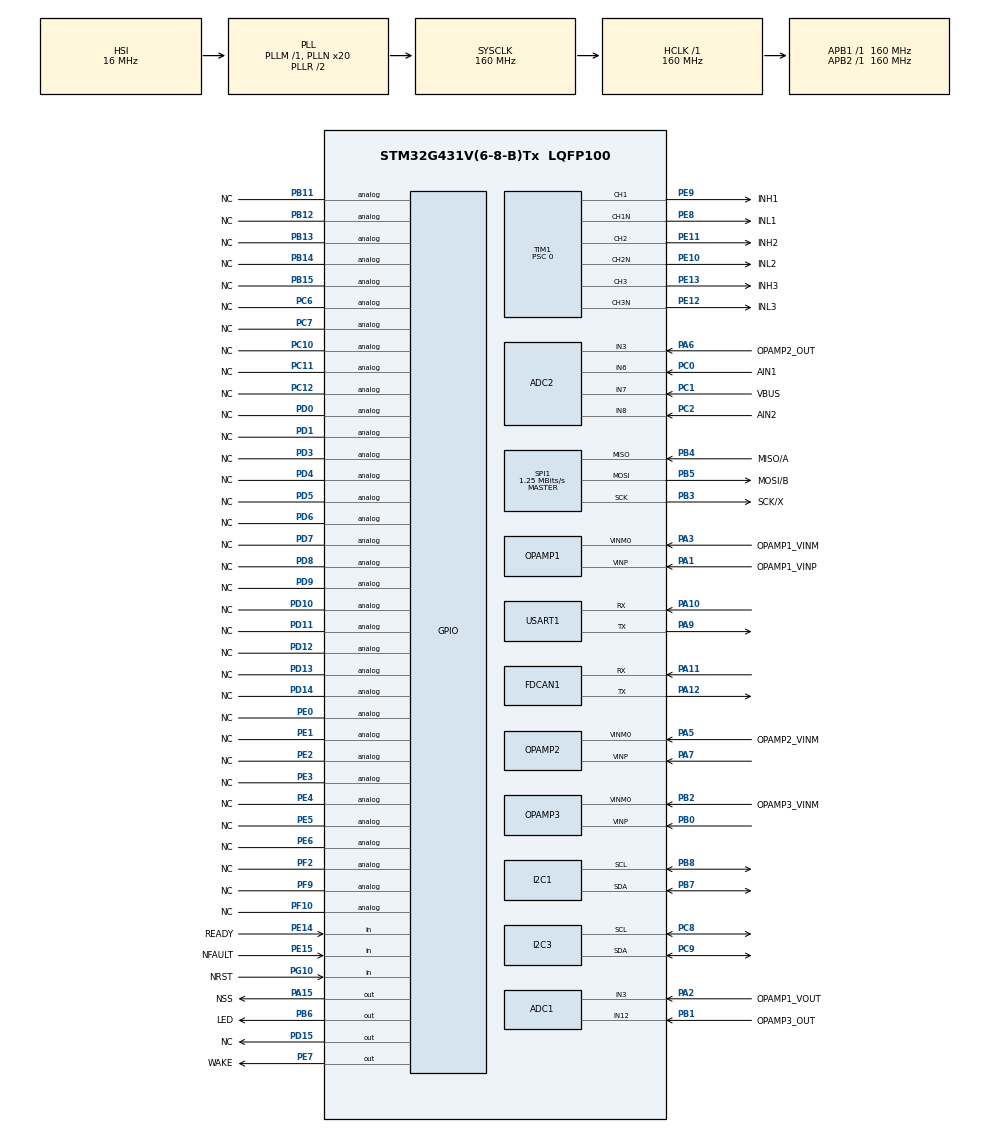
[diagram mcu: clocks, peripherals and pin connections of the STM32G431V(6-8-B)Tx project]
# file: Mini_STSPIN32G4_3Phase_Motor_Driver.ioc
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ADC1.Channel-0\#ChannelRegularConversion=ADC_CHANNEL_3
ADC1.Channel-5\#ChannelRegularConversion=ADC_CHANNEL_12
ADC1.Channel-6\#ChannelRegularConversion=ADC_CHANNEL_TEMPSENSOR_ADC1
ADC1.Channel-7\#ChannelRegularConversion=ADC_CHANNEL_VREFINT
ADC1.ContinuousConvMode=DISABLE
ADC1.DMAContinuousRequests=ENABLE
ADC1.EOCSelection=ADC_EOC_SEQ_CONV
ADC1.EnableInjectedConversion=DISABLE
ADC1.ExternalTrigConv=ADC_EXTERNALTRIG_T1_TRGO
ADC1.Mode=ADC_MODE_INDEPENDENT
ADC1.NbrOfConversion=4
ADC1.NbrOfConversionFlag=1
ADC1.OffsetNumber-0\#ChannelRegularConversion=ADC_OFFSET_NONE
ADC1.OffsetNumber-5\#ChannelRegularConversion=ADC_OFFSET_NONE
ADC1.OffsetNumber-6\#ChannelRegularConversion=ADC_OFFSET_NONE
ADC1.OffsetNumber-7\#ChannelRegularConversion=ADC_OFFSET_NONE
ADC1.Overrun=ADC_OVR_DATA_OVERWRITTEN
ADC1.OversamplingMode=DISABLE
ADC1.Rank-0\#ChannelRegularConversion=1
ADC1.Rank-5\#ChannelRegularConversion=2
ADC1.Rank-6\#ChannelRegularConversion=3
ADC1.Rank-7\#ChannelRegularConversion=4
ADC1.Rank1_Channel=ADC_CHANNEL_3
ADC1.Rank2_Channel=ADC_CHANNEL_3
ADC1.Rank3_Channel=ADC_CHANNEL_3
ADC1.Rank4_Channel=ADC_CHANNEL_3
ADC1.SamplingTime-0\#ChannelRegularConversion=ADC_SAMPLETIME_6CYCLES_5
ADC1.SamplingTime-5\#ChannelRegularConversion=ADC_SAMPLETIME_6CYCLES_5
ADC1.SamplingTime-6\#ChannelRegularConversion=ADC_SAMPLETIME_247CYCLES_5
ADC1.SamplingTime-7\#ChannelRegularConversion=ADC_SAMPLETIME_247CYCLES_5
ADC1.master=1
ADC2.Channel-5\#ChannelRegularConversion=ADC_CHANNEL_3
ADC2.Channel-6\#ChannelRegularConversion=ADC_CHANNEL_8
ADC2.Channel-7\#ChannelRegularConversion=ADC_CHANNEL_6
ADC2.Channel-8\#ChannelRegularConversion=ADC_CHANNEL_7
ADC2.ContinuousConvMode=DISABLE
ADC2.DMAContinuousRequests=ENABLE
ADC2.EOCSelection=ADC_EOC_SEQ_CONV
ADC2.EnableInjectedConversion=DISABLE
ADC2.EnableRegularConversion=ENABLE
ADC2.ExternalTrigConv=ADC_EXTERNALTRIG_T1_TRGO
ADC2.NbrOfConversion=4
ADC2.NbrOfConversionFlag=1
ADC2.OffsetNumber-5\#ChannelRegularConversion=ADC_OFFSET_NONE
ADC2.OffsetNumber-6\#ChannelRegularConversion=ADC_OFFSET_NONE
ADC2.OffsetNumber-7\#ChannelRegularConversion=ADC_OFFSET_NONE
ADC2.OffsetNumber-8\#ChannelRegularConversion=ADC_OFFSET_NONE
ADC2.Overrun=ADC_OVR_DATA_OVERWRITTEN
ADC2.OversamplingMode=DISABLE
ADC2.Rank-5\#ChannelRegularConversion=1
ADC2.Rank-6\#ChannelRegularConversion=2
ADC2.Rank-7\#ChannelRegularConversion=3
ADC2.Rank-8\#ChannelRegularConversion=4
ADC2.Rank1_Channel=ADC_CHANNEL_3
ADC2.Rank2_Channel=ADC_CHANNEL_6
ADC2.Rank3_Channel=ADC_CHANNEL_7
ADC2.Rank4_Channel=ADC_CHANNEL_8
ADC2.SamplingTime-5\#ChannelRegularConversion=ADC_SAMPLETIME_6CYCLES_5
ADC2.SamplingTime-6\#ChannelRegularConversion=ADC_SAMPLETIME_6CYCLES_5
ADC2.SamplingTime-7\#ChannelRegularConversion=ADC_SAMPLETIME_6CYCLES_5
ADC2.SamplingTime-8\#ChannelRegularConversion=ADC_SAMPLETIME_6CYCLES_5
Dma.ADC1.1.Direction=DMA_PERIPH_TO_MEMORY
Dma.ADC1.1.EventEnable=DISABLE
Dma.ADC1.1.Instance=DMA1_Channel2
Dma.ADC1.1.MemDataAlignment=DMA_MDATAALIGN_HALFWORD
Dma.ADC1.1.MemInc=DMA_MINC_ENABLE
Dma.ADC1.1.Mode=DMA_CIRCULAR
Dma.ADC1.1.PeriphDataAlignment=DMA_PDATAALIGN_HALFWORD
Dma.ADC1.1.PeriphInc=DMA_PINC_DISABLE
Dma.ADC1.1.Polarity=HAL_DMAMUX_REQ_GEN_RISING
Dma.ADC1.1.Priority=DMA_PRIORITY_HIGH
Dma.ADC1.1.RequestNumber=1
Dma.ADC1.1.SignalID=NONE
Dma.ADC1.1.SyncEnable=DISABLE
Dma.ADC1.1.SyncPolarity=HAL_DMAMUX_SYNC_NO_EVENT
Dma.ADC1.1.SyncRequestNumber=1
Dma.ADC1.1.SyncSignalID=NONE
Dma.ADC2.0.Direction=DMA_PERIPH_TO_MEMORY
Dma.ADC2.0.EventEnable=DISABLE
Dma.ADC2.0.Instance=DMA1_Channel3
Dma.ADC2.0.MemDataAlignment=DMA_MDATAALIGN_HALFWORD
Dma.ADC2.0.MemInc=DMA_MINC_ENABLE
Dma.ADC2.0.Mode=DMA_CIRCULAR
Dma.ADC2.0.PeriphDataAlignment=DMA_PDATAALIGN_HALFWORD
Dma.ADC2.0.PeriphInc=DMA_PINC_DISABLE
Dma.ADC2.0.Polarity=HAL_DMAMUX_REQ_GEN_RISING
Dma.ADC2.0.Priority=DMA_PRIORITY_HIGH
Dma.ADC2.0.RequestNumber=1
Dma.ADC2.0.SignalID=NONE
Dma.ADC2.0.SyncEnable=DISABLE
Dma.ADC2.0.SyncPolarity=HAL_DMAMUX_SYNC_NO_EVENT
Dma.ADC2.0.SyncRequestNumber=1
Dma.ADC2.0.SyncSignalID=NONE
Dma.MEMTOMEM.3.Direction=DMA_MEMORY_TO_MEMORY
Dma.MEMTOMEM.3.EventEnable=DISABLE
Dma.MEMTOMEM.3.Instance=DMA1_Channel4
Dma.MEMTOMEM.3.MemDataAlignment=DMA_MDATAALIGN_HALFWORD
Dma.MEMTOMEM.3.MemInc=DMA_MINC_ENABLE
Dma.MEMTOMEM.3.Mode=DMA_NORMAL
Dma.MEMTOMEM.3.PeriphDataAlignment=DMA_PDATAALIGN_HALFWORD
Dma.MEMTOMEM.3.PeriphInc=DMA_PINC_ENABLE
Dma.MEMTOMEM.3.Polarity=HAL_DMAMUX_REQ_GEN_RISING
Dma.MEMTOMEM.3.Priority=DMA_PRIORITY_LOW
Dma.MEMTOMEM.3.RequestNumber=1
Dma.MEMTOMEM.3.SignalID=NONE
Dma.MEMTOMEM.3.SyncEnable=DISABLE
Dma.MEMTOMEM.3.SyncPolarity=HAL_DMAMUX_SYNC_NO_EVENT
Dma.MEMTOMEM.3.SyncRequestNumber=1
Dma.MEMTOMEM.3.SyncSignalID=NONE
Dma.MEMTOMEM.4.Direction=DMA_MEMORY_TO_MEMORY
Dma.MEMTOMEM.4.EventEnable=DISABLE
Dma.MEMTOMEM.4.Instance=DMA1_Channel5
Dma.MEMTOMEM.4.MemDataAlignment=DMA_MDATAALIGN_HALFWORD
Dma.MEMTOMEM.4.MemInc=DMA_MINC_ENABLE
Dma.MEMTOMEM.4.Mode=DMA_NORMAL
Dma.MEMTOMEM.4.PeriphDataAlignment=DMA_PDATAALIGN_HALFWORD
Dma.MEMTOMEM.4.PeriphInc=DMA_PINC_ENABLE
Dma.MEMTOMEM.4.Polarity=HAL_DMAMUX_REQ_GEN_RISING
Dma.MEMTOMEM.4.Priority=DMA_PRIORITY_LOW
Dma.MEMTOMEM.4.RequestNumber=1
Dma.MEMTOMEM.4.SignalID=NONE
Dma.MEMTOMEM.4.SyncEnable=DISABLE
Dma.MEMTOMEM.4.SyncPolarity=HAL_DMAMUX_SYNC_NO_EVENT
Dma.MEMTOMEM.4.SyncRequestNumber=1
Dma.MEMTOMEM.4.SyncSignalID=NONE
Dma.Request0=ADC2
Dma.Request1=ADC1
Dma.Request2=USART1_TX
Dma.Request3=MEMTOMEM
Dma.Request4=MEMTOMEM
Dma.Request5=SPI1_RX
Dma.Request6=SPI1_TX
Dma.SPI1_RX.5.Direction=DMA_PERIPH_TO_MEMORY
Dma.SPI1_RX.5.EventEnable=DISABLE
Dma.SPI1_RX.5.Instance=DMA2_Channel1
Dma.SPI1_RX.5.MemDataAlignment=DMA_MDATAALIGN_HALFWORD
Dma.SPI1_RX.5.MemInc=DMA_MINC_ENABLE
Dma.SPI1_RX.5.Mode=DMA_NORMAL
Dma.SPI1_RX.5.PeriphDataAlignment=DMA_PDATAALIGN_HALFWORD
Dma.SPI1_RX.5.PeriphInc=DMA_PINC_DISABLE
Dma.SPI1_RX.5.Polarity=HAL_DMAMUX_REQ_GEN_RISING
Dma.SPI1_RX.5.Priority=DMA_PRIORITY_VERY_HIGH
Dma.SPI1_RX.5.RequestNumber=1
Dma.SPI1_RX.5.SignalID=NONE
Dma.SPI1_RX.5.SyncEnable=DISABLE
Dma.SPI1_RX.5.SyncPolarity=HAL_DMAMUX_SYNC_NO_EVENT
Dma.SPI1_RX.5.SyncRequestNumber=1
Dma.SPI1_RX.5.SyncSignalID=NONE
Dma.SPI1_TX.6.Direction=DMA_MEMORY_TO_PERIPH
Dma.SPI1_TX.6.EventEnable=DISABLE
Dma.SPI1_TX.6.Instance=DMA2_Channel2
Dma.SPI1_TX.6.MemDataAlignment=DMA_MDATAALIGN_HALFWORD
Dma.SPI1_TX.6.MemInc=DMA_MINC_ENABLE
Dma.SPI1_TX.6.Mode=DMA_NORMAL
Dma.SPI1_TX.6.PeriphDataAlignment=DMA_PDATAALIGN_HALFWORD
Dma.SPI1_TX.6.PeriphInc=DMA_PINC_DISABLE
Dma.SPI1_TX.6.Polarity=HAL_DMAMUX_REQ_GEN_RISING
Dma.SPI1_TX.6.Priority=DMA_PRIORITY_VERY_HIGH
Dma.SPI1_TX.6.RequestNumber=1
Dma.SPI1_TX.6.SignalID=NONE
Dma.SPI1_TX.6.SyncEnable=DISABLE
Dma.SPI1_TX.6.SyncPolarity=HAL_DMAMUX_SYNC_NO_EVENT
Dma.SPI1_TX.6.SyncRequestNumber=1
Dma.SPI1_TX.6.SyncSignalID=NONE
Dma.USART1_TX.2.Direction=DMA_MEMORY_TO_PERIPH
Dma.USART1_TX.2.EventEnable=DISABLE
Dma.USART1_TX.2.Instance=DMA1_Channel1
Dma.USART1_TX.2.MemDataAlignment=DMA_MDATAALIGN_BYTE
Dma.USART1_TX.2.MemInc=DMA_MINC_ENABLE
Dma.USART1_TX.2.Mode=DMA_NORMAL
Dma.USART1_TX.2.PeriphDataAlignment=DMA_PDATAALIGN_BYTE
Dma.USART1_TX.2.PeriphInc=DMA_PINC_DISABLE
Dma.USART1_TX.2.Polarity=HAL_DMAMUX_REQ_GEN_RISING
Dma.USART1_TX.2.Priority=DMA_PRIORITY_LOW
Dma.USART1_TX.2.RequestNumber=1
Dma.USART1_TX.2.SignalID=NONE
Dma.USART1_TX.2.SyncEnable=DISABLE
Dma.USART1_TX.2.SyncPolarity=HAL_DMAMUX_SYNC_NO_EVENT
Dma.USART1_TX.2.SyncRequestNumber=1
Dma.USART1_TX.2.SyncSignalID=NONE
FDCAN1.CalculateBaudRateNominal=3333333
FDCAN1.CalculateTimeBitNominal=300
FDCAN1.CalculateTimeQuantumNominal=100.0
I2C1.Timing=0x30D29DE4
I2C3.Timing=0x30D29DE4
Mcu.Family=STM32G4
Mcu.Name=STM32G431V(6-8-B)Tx
Mcu.Package=LQFP100
Mcu.UserConstants=TIM1_COUNT_MAX,8000
NVIC.ADC1_2_IRQn=true\:0\:0\:true\:false\:true\:true\:true\:true
NVIC.DMA1_Channel1_IRQn=true\:1\:0\:true\:false\:true\:false\:true\:true
NVIC.DMA1_Channel2_IRQn=true\:1\:0\:true\:false\:true\:false\:true\:true
NVIC.DMA1_Channel3_IRQn=true\:1\:0\:true\:false\:true\:false\:true\:true
NVIC.DMA2_Channel1_IRQn=true\:0\:0\:false\:false\:true\:false\:true\:true
NVIC.DMA2_Channel2_IRQn=true\:0\:0\:false\:false\:true\:false\:true\:true
NVIC.PriorityGroup=NVIC_PRIORITYGROUP_4
NVIC.SPI1_IRQn=true\:0\:0\:false\:false\:true\:true\:true\:true
NVIC.TIM1_UP_TIM16_IRQn=true\:2\:0\:true\:false\:true\:true\:true\:true
NVIC.USART1_IRQn=true\:0\:0\:true\:false\:true\:true\:true\:true
OPAMP1.PgaGain=OPAMP_PGA_GAIN_16_OR_MINUS_15
OPAMP1.PowerMode=OPAMP_POWERMODE_HIGHSPEED
OPAMP2.PgaGain=OPAMP_PGA_GAIN_16_OR_MINUS_15
OPAMP2.PowerMode=OPAMP_POWERMODE_HIGHSPEED
OPAMP3.PgaGain=OPAMP_PGA_GAIN_16_OR_MINUS_15
OPAMP3.PowerMode=OPAMP_POWERMODE_HIGHSPEED
PA1.GPIO_Label=OPAMP1_VINP
PA1.Mode=PGA Connected-INVERTINGINPUT_IO0_BIAS
PA1.Signal=OPAMP1_VINP
PA10.Mode=Asynchronous
PA10.Signal=USART1_RX
PA11.Mode=FDCAN_Activate
PA11.Signal=FDCAN1_RX
PA12.Mode=FDCAN_Activate
PA12.Signal=FDCAN1_TX
PA13.GPIO_Label=SWDIO
PA13.Mode=Serial_Wire
PA13.Signal=SYS_JTMS-SWDIO
PA14.GPIO_Label=SWCLK
PA14.Mode=Serial_Wire
PA14.Signal=SYS_JTCK-SWCLK
PA15.GPIO_Label=NSS
PA15.Signal=GPIO_Output
PA2.GPIO_Label=OPAMP1_VOUT
PA2.Signal=SharedAnalog_PA2
PA3.GPIO_Label=OPAMP1_VINM
PA3.Mode=PGA Connected-INVERTINGINPUT_IO0_BIAS
PA3.Signal=OPAMP1_VINM0
PA5.GPIO_Label=OPAMP2_VINM
PA5.Mode=PGA Connected-INVERTINGINPUT_IO0_BIAS
PA5.Signal=OPAMP2_VINM0
PA6.GPIO_Label=OPAMP2_OUT
PA6.Signal=SharedAnalog_PA6
PA7.Mode=PGA Connected-INVERTINGINPUT_IO0_BIAS
PA7.Signal=OPAMP2_VINP
PA9.Mode=Asynchronous
PA9.Signal=USART1_TX
PB0.Mode=PGA Connected-INVERTINGINPUT_IO0_BIAS
PB0.Signal=OPAMP3_VINP
PB1.GPIO_Label=OPAMP3_OUT
PB1.Signal=SharedAnalog_PB1
PB11.GPIO_Label=NC
PB11.Signal=GPIO_Analog
PB12.GPIO_Label=NC
PB12.Signal=GPIO_Analog
PB13.GPIO_Label=NC
PB13.Signal=GPIO_Analog
PB14.GPIO_Label=NC
PB14.Signal=GPIO_Analog
PB15.GPIO_Label=NC
PB15.Signal=GPIO_Analog
PB2.GPIO_Label=OPAMP3_VINM
PB2.Mode=PGA Connected-INVERTINGINPUT_IO0_BIAS
PB2.Signal=OPAMP3_VINM0
PB3.GPIO_Label=SCK/X
PB3.Mode=Full_Duplex_Master
PB3.Signal=SPI1_SCK
PB4.GPIO_Label=MISO/A
PB4.Mode=Full_Duplex_Master
PB4.Signal=SPI1_MISO
PB5.GPIO_Label=MOSI/B
PB5.Mode=Full_Duplex_Master
PB5.Signal=SPI1_MOSI
PB6.GPIO_Label=LED
PB6.Signal=GPIO_Output
PB7.Mode=I2C
PB7.Signal=I2C1_SDA
PB8-BOOT0.Mode=I2C
PB8-BOOT0.Signal=I2C1_SCL
PC0.GPIO_Label=AIN1
PC0.Mode=IN6-Single-Ended
PC0.Signal=ADC2_IN6
PC1.GPIO_Label=VBUS
PC1.Mode=IN7-Single-Ended
PC1.Signal=ADC2_IN7
PC10.GPIO_Label=NC
PC10.Signal=GPIO_Analog
PC11.GPIO_Label=NC
PC11.Signal=GPIO_Analog
PC12.GPIO_Label=NC
PC12.Signal=GPIO_Analog
PC2.GPIO_Label=AIN2
PC2.Mode=IN8-Single-Ended
PC2.Signal=ADC2_IN8
PC6.GPIO_Label=NC
PC6.Signal=GPIO_Analog
PC7.GPIO_Label=NC
PC7.Signal=GPIO_Analog
PC8.Mode=I2C
PC8.Signal=I2C3_SCL
PC9.Mode=I2C
PC9.Signal=I2C3_SDA
PD0.GPIO_Label=NC
PD0.Signal=GPIO_Analog
PD1.GPIO_Label=NC
PD1.Signal=GPIO_Analog
PD10.GPIO_Label=NC
PD10.Signal=GPIO_Analog
PD11.GPIO_Label=NC
PD11.Signal=GPIO_Analog
PD12.GPIO_Label=NC
PD12.Signal=GPIO_Analog
PD13.GPIO_Label=NC
PD13.Signal=GPIO_Analog
PD14.GPIO_Label=NC
PD14.Signal=GPIO_Analog
PD15.GPIO_Label=NC
PD15.Signal=GPIO_Output
PD3.GPIO_Label=NC
PD3.Signal=GPIO_Analog
PD4.GPIO_Label=NC
PD4.Signal=GPIO_Analog
PD5.GPIO_Label=NC
PD5.Signal=GPIO_Analog
PD6.GPIO_Label=NC
PD6.Signal=GPIO_Analog
PD7.GPIO_Label=NC
PD7.Signal=GPIO_Analog
PD8.GPIO_Label=NC
PD8.Signal=GPIO_Analog
PD9.GPIO_Label=NC
PD9.Signal=GPIO_Analog
PE0.GPIO_Label=NC
PE0.Signal=GPIO_Analog
PE1.GPIO_Label=NC
PE1.Signal=GPIO_Analog
PE10.GPIO_Label=INL2
PE10.Mode=PWM Generation2 CH2 CH2N
PE10.Signal=TIM1_CH2N
PE11.GPIO_Label=INH2
PE11.Signal=S_TIM1_CH2
PE12.GPIO_Label=INL3
PE12.Mode=PWM Generation3 CH3 CH3N
PE12.Signal=TIM1_CH3N
PE13.GPIO_Label=INH3
PE13.Signal=S_TIM1_CH3
PE14.GPIO_Label=READY
PE14.Signal=GPIO_Input
PE15.GPIO_Label=NFAULT
PE15.Signal=GPIO_Input
PE2.GPIO_Label=NC
PE2.Signal=GPIO_Analog
PE3.GPIO_Label=NC
PE3.Signal=GPIO_Analog
PE4.GPIO_Label=NC
PE4.Signal=GPIO_Analog
PE5.GPIO_Label=NC
PE5.Signal=GPIO_Analog
PE6.GPIO_Label=NC
PE6.Signal=GPIO_Analog
PE7.GPIO_Label=WAKE
PE7.Signal=GPIO_Output
PE8.GPIO_Label=INL1
PE8.Mode=PWM Generation1 CH1 CH1N
PE8.Signal=TIM1_CH1N
PE9.GPIO_Label=INH1
PE9.Signal=S_TIM1_CH1
PF0-OSC_IN.Mode=HSE-External-Oscillator
PF0-OSC_IN.Signal=RCC_OSC_IN
PF1-OSC_OUT.Mode=HSE-External-Oscillator
PF1-OSC_OUT.Signal=RCC_OSC_OUT
PF10.GPIO_Label=NC
PF10.Signal=GPIO_Analog
PF2.GPIO_Label=NC
PF2.Signal=GPIO_Analog
PF9.GPIO_Label=NC
PF9.Signal=GPIO_Analog
PG10-NRST.GPIO_Label=NRST
PG10-NRST.Signal=GPIO_Input
ProjectManager.HeapSize=0x200
ProjectManager.StackSize=0x400
ProjectManager.TargetToolchain=CMake
RCC.ADC12Freq_Value=160000000
RCC.AHBFreq_Value=160000000
RCC.APB1Freq_Value=160000000
RCC.APB1TimFreq_Value=160000000
RCC.APB2Freq_Value=160000000
RCC.APB2TimFreq_Value=160000000
RCC.CortexFreq_Value=160000000
RCC.EXTERNAL_CLOCK_VALUE=12288000
RCC.HCLKFreq_Value=160000000
RCC.HSE_VALUE=16000000
RCC.HSI48_VALUE=48000000
RCC.HSI_VALUE=16000000
RCC.LSE_VALUE=32768
RCC.PLLN=20
RCC.SYSCLKFreq_VALUE=160000000
RCC.SYSCLKSource=RCC_SYSCLKSOURCE_PLLCLK
RCC.USBFreq_Value=160000000
RCC.VCOOutputFreq_Value=320000000
SH.S_TIM1_CH1.0=TIM1_CH1,PWM Generation1 CH1 CH1N
SH.S_TIM1_CH2.0=TIM1_CH2,PWM Generation2 CH2 CH2N
SH.S_TIM1_CH3.0=TIM1_CH3,PWM Generation3 CH3 CH3N
SH.SharedAnalog_PA2.0=ADC1_IN3,IN3-Single-Ended
SH.SharedAnalog_PA2.1=OPAMP1_VOUT,PGA Connected-INVERTINGINPUT_IO0_BIAS
SH.SharedAnalog_PA6.0=ADC2_IN3,IN3-Single-Ended
SH.SharedAnalog_PA6.1=OPAMP2_VOUT,PGA Connected-INVERTINGINPUT_IO0_BIAS
SH.SharedAnalog_PB1.0=ADC1_IN12,IN12-Single-Ended
SH.SharedAnalog_PB1.1=OPAMP3_VOUT,PGA Connected-INVERTINGINPUT_IO0_BIAS
SPI1.BaudRatePrescaler=SPI_BAUDRATEPRESCALER_128
SPI1.CLKPhase=SPI_PHASE_2EDGE
SPI1.CalculateBaudRate=1.25 MBits/s
SPI1.DataSize=SPI_DATASIZE_16BIT
SPI1.Direction=SPI_DIRECTION_2LINES
SPI1.Mode=SPI_MODE_MASTER
SPI1.VirtualType=VM_MASTER
TIM1.AutoReloadPreload=TIM_AUTORELOAD_PRELOAD_ENABLE
TIM1.Channel-PWM\ Generation1\ CH1\ CH1N=TIM_CHANNEL_1
TIM1.Channel-PWM\ Generation2\ CH2\ CH2N=TIM_CHANNEL_2
TIM1.Channel-PWM\ Generation3\ CH3\ CH3N=TIM_CHANNEL_3
TIM1.CounterMode=TIM_COUNTERMODE_CENTERALIGNED2
TIM1.OC1Preload_PWM=ENABLE
TIM1.OCMode_PWM-PWM\ Generation1\ CH1\ CH1N=TIM_OCMODE_PWM2
TIM1.OCMode_PWM-PWM\ Generation2\ CH2\ CH2N=TIM_OCMODE_PWM2
TIM1.OCMode_PWM-PWM\ Generation3\ CH3\ CH3N=TIM_OCMODE_PWM2
TIM1.PeriodNoDither=TIM1_COUNT_MAX
TIM1.Prescaler=0
TIM1.PulseNoDither_1=TIM1_COUNT_MAX
TIM1.PulseNoDither_2=TIM1_COUNT_MAX
TIM1.PulseNoDither_3=TIM1_COUNT_MAX
TIM1.RepetitionCounter=1
TIM1.TIM_MasterOutputTrigger=TIM_TRGO_UPDATE
TIM1.TIM_MasterOutputTrigger2=TIM_TRGO2_RESET
TIM1.TIM_MasterSlaveMode=TIM_MASTERSLAVEMODE_DISABLE
USART1.VirtualMode-Asynchronous=VM_ASYNC
VP_ADC1_TempSens_Input.Mode=IN-TempSens
VP_ADC1_Vref_Input.Mode=IN-Vrefint
VP_SYS_VS_DBSignals.Mode=DisableDeadBatterySignals
VP_TIM1_VS_ClockSourceINT.Mode=Internal
VP_TIM4_VS_ClockSourceINT.Mode=Internal
board=custom

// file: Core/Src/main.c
/* USER CODE BEGIN Header */
/**
  ******************************************************************************
  * @file           : main.c
  * @brief          : Main program body
  ******************************************************************************
  * @attention
  *
  * Copyright (c) 2026 STMicroelectronics.
  * All rights reserved.
  *
  * This software is licensed under terms that can be found in the LICENSE file
  * in the root directory of this software component.
  * If no LICENSE file comes with this software, it is provided AS-IS.
  *
  ******************************************************************************
  */
/* USER CODE END Header */
#include "main.h"

/* USER CODE BEGIN Includes */
#include "main_task.h"
/* USER CODE END Includes */

ADC_HandleTypeDef hadc1;
ADC_HandleTypeDef hadc2;
DMA_HandleTypeDef hdma_adc1;
DMA_HandleTypeDef hdma_adc2;

FDCAN_HandleTypeDef hfdcan1;

I2C_HandleTypeDef hi2c1;
I2C_HandleTypeDef hi2c3;

OPAMP_HandleTypeDef hopamp1;
OPAMP_HandleTypeDef hopamp2;
OPAMP_HandleTypeDef hopamp3;

SPI_HandleTypeDef hspi1;
DMA_HandleTypeDef hdma_spi1_rx;
DMA_HandleTypeDef hdma_spi1_tx;

TIM_HandleTypeDef htim1;
TIM_HandleTypeDef htim4;

UART_HandleTypeDef huart1;
DMA_HandleTypeDef hdma_usart1_tx;

DMA_HandleTypeDef hdma_memtomem_dma1_channel4;
DMA_HandleTypeDef hdma_memtomem_dma1_channel5;

void SystemClock_Config(void);
static void MX_GPIO_Init(void);
static void MX_DMA_Init(void);
static void MX_ADC1_Init(void);
static void MX_ADC2_Init(void);
static void MX_FDCAN1_Init(void);
static void MX_OPAMP1_Init(void);
static void MX_OPAMP2_Init(void);
static void MX_OPAMP3_Init(void);
static void MX_TIM1_Init(void);
static void MX_I2C1_Init(void);
static void MX_I2C3_Init(void);
static void MX_USART1_UART_Init(void);
static void MX_SPI1_Init(void);
static void MX_TIM4_Init(void);

int main(void)
{

  /* MCU Configuration--------------------------------------------------------*/

  /* Reset of all peripherals, Initializes the Flash interface and the Systick. */
  HAL_Init();

  /* Configure the system clock */
  SystemClock_Config();

  /* Initialize all configured peripherals */
  MX_GPIO_Init();
  MX_DMA_Init();
  MX_ADC1_Init();
  MX_ADC2_Init();
  MX_FDCAN1_Init();
  MX_OPAMP1_Init();
  MX_OPAMP2_Init();
  MX_OPAMP3_Init();
  MX_TIM1_Init();
  MX_I2C1_Init();
  MX_I2C3_Init();
  MX_USART1_UART_Init();
  MX_SPI1_Init();
  MX_TIM4_Init();

  /* Infinite loop */
  /* USER CODE BEGIN WHILE */
  while (1)
  {
    main_task();
    /* USER CODE END WHILE */

  }
}

void SystemClock_Config(void)
{
  RCC_OscInitTypeDef RCC_OscInitStruct = {0};
  RCC_ClkInitTypeDef RCC_ClkInitStruct = {0};

  /** Configure the main internal regulator output voltage
  */
  HAL_PWREx_ControlVoltageScaling(PWR_REGULATOR_VOLTAGE_SCALE1_BOOST);

  /** Initializes the RCC Oscillators according to the specified parameters
  * in the RCC_OscInitTypeDef structure.
  */
  RCC_OscInitStruct.OscillatorType = RCC_OSCILLATORTYPE_HSI;
  RCC_OscInitStruct.HSIState = RCC_HSI_ON;
  RCC_OscInitStruct.HSICalibrationValue = RCC_HSICALIBRATION_DEFAULT;
  RCC_OscInitStruct.PLL.PLLState = RCC_PLL_ON;
  RCC_OscInitStruct.PLL.PLLSource = RCC_PLLSOURCE_HSI;
  RCC_OscInitStruct.PLL.PLLM = RCC_PLLM_DIV1;
  RCC_OscInitStruct.PLL.PLLN = 20;
  RCC_OscInitStruct.PLL.PLLP = RCC_PLLP_DIV2;
  RCC_OscInitStruct.PLL.PLLQ = RCC_PLLQ_DIV2;
  RCC_OscInitStruct.PLL.PLLR = RCC_PLLR_DIV2;
  if (HAL_RCC_OscConfig(&RCC_OscInitStruct) != HAL_OK)
  {
    Error_Handler();
  }

  /** Initializes the CPU, AHB and APB buses clocks
  */
  RCC_ClkInitStruct.ClockType = RCC_CLOCKTYPE_HCLK|RCC_CLOCKTYPE_SYSCLK
                              |RCC_CLOCKTYPE_PCLK1|RCC_CLOCKTYPE_PCLK2;
  RCC_ClkInitStruct.SYSCLKSource = RCC_SYSCLKSOURCE_PLLCLK;
  RCC_ClkInitStruct.AHBCLKDivider = RCC_SYSCLK_DIV1;
  RCC_ClkInitStruct.APB1CLKDivider = RCC_HCLK_DIV1;
  RCC_ClkInitStruct.APB2CLKDivider = RCC_HCLK_DIV1;

  if (HAL_RCC_ClockConfig(&RCC_ClkInitStruct, FLASH_LATENCY_4) != HAL_OK)
  {
    Error_Handler();
  }
}

static void MX_ADC1_Init(void)
{

  ADC_MultiModeTypeDef multimode = {0};
  ADC_ChannelConfTypeDef sConfig = {0};

  /** Common config
  */
  hadc1.Instance = ADC1;
  hadc1.Init.ClockPrescaler = ADC_CLOCK_SYNC_PCLK_DIV4;
  hadc1.Init.Resolution = ADC_RESOLUTION_12B;
  hadc1.Init.DataAlign = ADC_DATAALIGN_RIGHT;
  hadc1.Init.GainCompensation = 0;
  hadc1.Init.ScanConvMode = ADC_SCAN_ENABLE;
  hadc1.Init.EOCSelection = ADC_EOC_SEQ_CONV;
  hadc1.Init.LowPowerAutoWait = DISABLE;
  hadc1.Init.ContinuousConvMode = DISABLE;
  hadc1.Init.NbrOfConversion = 4;
  hadc1.Init.DiscontinuousConvMode = DISABLE;
  hadc1.Init.ExternalTrigConv = ADC_EXTERNALTRIG_T1_TRGO;
  hadc1.Init.ExternalTrigConvEdge = ADC_EXTERNALTRIGCONVEDGE_RISING;
  hadc1.Init.DMAContinuousRequests = ENABLE;
  hadc1.Init.Overrun = ADC_OVR_DATA_OVERWRITTEN;
  hadc1.Init.OversamplingMode = DISABLE;
  if (HAL_ADC_Init(&hadc1) != HAL_OK)
  {
    Error_Handler();
  }

  /** Configure the ADC multi-mode
  */
  multimode.Mode = ADC_MODE_INDEPENDENT;
  if (HAL_ADCEx_MultiModeConfigChannel(&hadc1, &multimode) != HAL_OK)
  {
    Error_Handler();
  }

  /** Configure Regular Channel
  */
  sConfig.Channel = ADC_CHANNEL_3;
  sConfig.Rank = ADC_REGULAR_RANK_1;
  sConfig.SamplingTime = ADC_SAMPLETIME_6CYCLES_5;
  sConfig.SingleDiff = ADC_SINGLE_ENDED;
  sConfig.OffsetNumber = ADC_OFFSET_NONE;
  sConfig.Offset = 0;
  if (HAL_ADC_ConfigChannel(&hadc1, &sConfig) != HAL_OK)
  {
    Error_Handler();
  }

  /** Configure Regular Channel
  */
  sConfig.Channel = ADC_CHANNEL_12;
  sConfig.Rank = ADC_REGULAR_RANK_2;
  if (HAL_ADC_ConfigChannel(&hadc1, &sConfig) != HAL_OK)
  {
    Error_Handler();
  }

  /** Configure Regular Channel
  */
  sConfig.Channel = ADC_CHANNEL_TEMPSENSOR_ADC1;
  sConfig.Rank = ADC_REGULAR_RANK_3;
  sConfig.SamplingTime = ADC_SAMPLETIME_247CYCLES_5;
  if (HAL_ADC_ConfigChannel(&hadc1, &sConfig) != HAL_OK)
  {
    Error_Handler();
  }

  /** Configure Regular Channel
  */
  sConfig.Channel = ADC_CHANNEL_VREFINT;
  sConfig.Rank = ADC_REGULAR_RANK_4;
  if (HAL_ADC_ConfigChannel(&hadc1, &sConfig) != HAL_OK)
  {
    Error_Handler();
  }

}

static void MX_ADC2_Init(void)
{

  ADC_ChannelConfTypeDef sConfig = {0};

  /** Common config
  */
  hadc2.Instance = ADC2;
  hadc2.Init.ClockPrescaler = ADC_CLOCK_SYNC_PCLK_DIV4;
  hadc2.Init.Resolution = ADC_RESOLUTION_12B;
  hadc2.Init.DataAlign = ADC_DATAALIGN_RIGHT;
  hadc2.Init.GainCompensation = 0;
  hadc2.Init.ScanConvMode = ADC_SCAN_ENABLE;
  hadc2.Init.EOCSelection = ADC_EOC_SEQ_CONV;
  hadc2.Init.LowPowerAutoWait = DISABLE;
  hadc2.Init.ContinuousConvMode = DISABLE;
  hadc2.Init.NbrOfConversion = 4;
  hadc2.Init.DiscontinuousConvMode = DISABLE;
  hadc2.Init.ExternalTrigConv = ADC_EXTERNALTRIG_T1_TRGO;
  hadc2.Init.ExternalTrigConvEdge = ADC_EXTERNALTRIGCONVEDGE_RISING;
  hadc2.Init.DMAContinuousRequests = ENABLE;
  hadc2.Init.Overrun = ADC_OVR_DATA_OVERWRITTEN;
  hadc2.Init.OversamplingMode = DISABLE;
  if (HAL_ADC_Init(&hadc2) != HAL_OK)
  {
    Error_Handler();
  }

  /** Configure Regular Channel
  */
  sConfig.Channel = ADC_CHANNEL_3;
  sConfig.Rank = ADC_REGULAR_RANK_1;
  sConfig.SamplingTime = ADC_SAMPLETIME_6CYCLES_5;
  sConfig.SingleDiff = ADC_SINGLE_ENDED;
  sConfig.OffsetNumber = ADC_OFFSET_NONE;
  sConfig.Offset = 0;
  if (HAL_ADC_ConfigChannel(&hadc2, &sConfig) != HAL_OK)
  {
    Error_Handler();
  }

  /** Configure Regular Channel
  */
  sConfig.Channel = ADC_CHANNEL_8;
  sConfig.Rank = ADC_REGULAR_RANK_2;
  if (HAL_ADC_ConfigChannel(&hadc2, &sConfig) != HAL_OK)
  {
    Error_Handler();
  }

  /** Configure Regular Channel
  */
  sConfig.Channel = ADC_CHANNEL_6;
  sConfig.Rank = ADC_REGULAR_RANK_3;
  if (HAL_ADC_ConfigChannel(&hadc2, &sConfig) != HAL_OK)
  {
    Error_Handler();
  }

  /** Configure Regular Channel
  */
  sConfig.Channel = ADC_CHANNEL_7;
  sConfig.Rank = ADC_REGULAR_RANK_4;
  if (HAL_ADC_ConfigChannel(&hadc2, &sConfig) != HAL_OK)
  {
    Error_Handler();
  }

}

static void MX_FDCAN1_Init(void)
{

  hfdcan1.Instance = FDCAN1;
  hfdcan1.Init.ClockDivider = FDCAN_CLOCK_DIV1;
  hfdcan1.Init.FrameFormat = FDCAN_FRAME_CLASSIC;
  hfdcan1.Init.Mode = FDCAN_MODE_NORMAL;
  hfdcan1.Init.AutoRetransmission = DISABLE;
  hfdcan1.Init.TransmitPause = DISABLE;
  hfdcan1.Init.ProtocolException = DISABLE;
  hfdcan1.Init.NominalPrescaler = 16;
  hfdcan1.Init.NominalSyncJumpWidth = 1;
  hfdcan1.Init.NominalTimeSeg1 = 1;
  hfdcan1.Init.NominalTimeSeg2 = 1;
  hfdcan1.Init.DataPrescaler = 1;
  hfdcan1.Init.DataSyncJumpWidth = 1;
  hfdcan1.Init.DataTimeSeg1 = 1;
  hfdcan1.Init.DataTimeSeg2 = 1;
  hfdcan1.Init.StdFiltersNbr = 0;
  hfdcan1.Init.ExtFiltersNbr = 0;
  hfdcan1.Init.TxFifoQueueMode = FDCAN_TX_FIFO_OPERATION;
  if (HAL_FDCAN_Init(&hfdcan1) != HAL_OK)
  {
    Error_Handler();
  }

}

static void MX_I2C1_Init(void)
{

  hi2c1.Instance = I2C1;
  hi2c1.Init.Timing = 0x30D29DE4;
  hi2c1.Init.OwnAddress1 = 0;
  hi2c1.Init.AddressingMode = I2C_ADDRESSINGMODE_7BIT;
  hi2c1.Init.DualAddressMode = I2C_DUALADDRESS_DISABLE;
  hi2c1.Init.OwnAddress2 = 0;
  hi2c1.Init.OwnAddress2Masks = I2C_OA2_NOMASK;
  hi2c1.Init.GeneralCallMode = I2C_GENERALCALL_DISABLE;
  hi2c1.Init.NoStretchMode = I2C_NOSTRETCH_DISABLE;
  if (HAL_I2C_Init(&hi2c1) != HAL_OK)
  {
    Error_Handler();
  }

  /** Configure Analogue filter
  */
  if (HAL_I2CEx_ConfigAnalogFilter(&hi2c1, I2C_ANALOGFILTER_ENABLE) != HAL_OK)
  {
    Error_Handler();
  }

  /** Configure Digital filter
  */
  if (HAL_I2CEx_ConfigDigitalFilter(&hi2c1, 0) != HAL_OK)
  {
    Error_Handler();
  }

}

static void MX_I2C3_Init(void)
{

  hi2c3.Instance = I2C3;
  hi2c3.Init.Timing = 0x30D29DE4;
  hi2c3.Init.OwnAddress1 = 0;
  hi2c3.Init.AddressingMode = I2C_ADDRESSINGMODE_7BIT;
  hi2c3.Init.DualAddressMode = I2C_DUALADDRESS_DISABLE;
  hi2c3.Init.OwnAddress2 = 0;
  hi2c3.Init.OwnAddress2Masks = I2C_OA2_NOMASK;
  hi2c3.Init.GeneralCallMode = I2C_GENERALCALL_DISABLE;
  hi2c3.Init.NoStretchMode = I2C_NOSTRETCH_DISABLE;
  if (HAL_I2C_Init(&hi2c3) != HAL_OK)
  {
    Error_Handler();
  }

  /** Configure Analogue filter
  */
  if (HAL_I2CEx_ConfigAnalogFilter(&hi2c3, I2C_ANALOGFILTER_ENABLE) != HAL_OK)
  {
    Error_Handler();
  }

  /** Configure Digital filter
  */
  if (HAL_I2CEx_ConfigDigitalFilter(&hi2c3, 0) != HAL_OK)
  {
    Error_Handler();
  }

}

static void MX_OPAMP1_Init(void)
{

  hopamp1.Instance = OPAMP1;
  hopamp1.Init.PowerMode = OPAMP_POWERMODE_HIGHSPEED;
  hopamp1.Init.Mode = OPAMP_PGA_MODE;
  hopamp1.Init.NonInvertingInput = OPAMP_NONINVERTINGINPUT_IO0;
  hopamp1.Init.InternalOutput = DISABLE;
  hopamp1.Init.TimerControlledMuxmode = OPAMP_TIMERCONTROLLEDMUXMODE_DISABLE;
  hopamp1.Init.PgaConnect = OPAMP_PGA_CONNECT_INVERTINGINPUT_IO0_BIAS;
  hopamp1.Init.PgaGain = OPAMP_PGA_GAIN_16_OR_MINUS_15;
  hopamp1.Init.UserTrimming = OPAMP_TRIMMING_FACTORY;
  if (HAL_OPAMP_Init(&hopamp1) != HAL_OK)
  {
    Error_Handler();
  }

}

static void MX_OPAMP2_Init(void)
{

  hopamp2.Instance = OPAMP2;
  hopamp2.Init.PowerMode = OPAMP_POWERMODE_HIGHSPEED;
  hopamp2.Init.Mode = OPAMP_PGA_MODE;
  hopamp2.Init.NonInvertingInput = OPAMP_NONINVERTINGINPUT_IO0;
  hopamp2.Init.InternalOutput = DISABLE;
  hopamp2.Init.TimerControlledMuxmode = OPAMP_TIMERCONTROLLEDMUXMODE_DISABLE;
  hopamp2.Init.PgaConnect = OPAMP_PGA_CONNECT_INVERTINGINPUT_IO0_BIAS;
  hopamp2.Init.PgaGain = OPAMP_PGA_GAIN_16_OR_MINUS_15;
  hopamp2.Init.UserTrimming = OPAMP_TRIMMING_FACTORY;
  if (HAL_OPAMP_Init(&hopamp2) != HAL_OK)
  {
    Error_Handler();
  }

}

static void MX_OPAMP3_Init(void)
{

  hopamp3.Instance = OPAMP3;
  hopamp3.Init.PowerMode = OPAMP_POWERMODE_HIGHSPEED;
  hopamp3.Init.Mode = OPAMP_PGA_MODE;
  hopamp3.Init.NonInvertingInput = OPAMP_NONINVERTINGINPUT_IO0;
  hopamp3.Init.InternalOutput = DISABLE;
  hopamp3.Init.TimerControlledMuxmode = OPAMP_TIMERCONTROLLEDMUXMODE_DISABLE;
  hopamp3.Init.PgaConnect = OPAMP_PGA_CONNECT_INVERTINGINPUT_IO0_BIAS;
  hopamp3.Init.PgaGain = OPAMP_PGA_GAIN_16_OR_MINUS_15;
  hopamp3.Init.UserTrimming = OPAMP_TRIMMING_FACTORY;
  if (HAL_OPAMP_Init(&hopamp3) != HAL_OK)
  {
    Error_Handler();
  }

}

static void MX_SPI1_Init(void)
{

  /* SPI1 parameter configuration*/
  hspi1.Instance = SPI1;
  hspi1.Init.Mode = SPI_MODE_MASTER;
  hspi1.Init.Direction = SPI_DIRECTION_2LINES;
  hspi1.Init.DataSize = SPI_DATASIZE_16BIT;
  hspi1.Init.CLKPolarity = SPI_POLARITY_LOW;
  hspi1.Init.CLKPhase = SPI_PHASE_2EDGE;
  hspi1.Init.NSS = SPI_NSS_SOFT;
  hspi1.Init.BaudRatePrescaler = SPI_BAUDRATEPRESCALER_128;
  hspi1.Init.FirstBit = SPI_FIRSTBIT_MSB;
  hspi1.Init.TIMode = SPI_TIMODE_DISABLE;
  hspi1.Init.CRCCalculation = SPI_CRCCALCULATION_DISABLE;
  hspi1.Init.CRCPolynomial = 7;
  hspi1.Init.CRCLength = SPI_CRC_LENGTH_DATASIZE;
  hspi1.Init.NSSPMode = SPI_NSS_PULSE_DISABLE;
  if (HAL_SPI_Init(&hspi1) != HAL_OK)
  {
    Error_Handler();
  }

}

static void MX_TIM1_Init(void)
{

  TIM_ClockConfigTypeDef sClockSourceConfig = {0};
  TIM_MasterConfigTypeDef sMasterConfig = {0};
  TIM_OC_InitTypeDef sConfigOC = {0};
  TIM_BreakDeadTimeConfigTypeDef sBreakDeadTimeConfig = {0};

  htim1.Instance = TIM1;
  htim1.Init.Prescaler = 0;
  htim1.Init.CounterMode = TIM_COUNTERMODE_CENTERALIGNED2;
  htim1.Init.Period = 8000;
  htim1.Init.ClockDivision = TIM_CLOCKDIVISION_DIV1;
  htim1.Init.RepetitionCounter = 1;
  htim1.Init.AutoReloadPreload = TIM_AUTORELOAD_PRELOAD_ENABLE;
  if (HAL_TIM_Base_Init(&htim1) != HAL_OK)
  {
    Error_Handler();
  }
  sClockSourceConfig.ClockSource = TIM_CLOCKSOURCE_INTERNAL;
  if (HAL_TIM_ConfigClockSource(&htim1, &sClockSourceConfig) != HAL_OK)
  {
    Error_Handler();
  }
  if (HAL_TIM_PWM_Init(&htim1) != HAL_OK)
  {
    Error_Handler();
  }
  sMasterConfig.MasterOutputTrigger = TIM_TRGO_UPDATE;
  sMasterConfig.MasterOutputTrigger2 = TIM_TRGO2_RESET;
  sMasterConfig.MasterSlaveMode = TIM_MASTERSLAVEMODE_DISABLE;
  if (HAL_TIMEx_MasterConfigSynchronization(&htim1, &sMasterConfig) != HAL_OK)
  {
    Error_Handler();
  }
  sConfigOC.OCMode = TIM_OCMODE_PWM2;
  sConfigOC.Pulse = 8000;
  sConfigOC.OCPolarity = TIM_OCPOLARITY_HIGH;
  sConfigOC.OCNPolarity = TIM_OCNPOLARITY_HIGH;
  sConfigOC.OCFastMode = TIM_OCFAST_DISABLE;
  sConfigOC.OCIdleState = TIM_OCIDLESTATE_RESET;
  sConfigOC.OCNIdleState = TIM_OCNIDLESTATE_RESET;
  if (HAL_TIM_PWM_ConfigChannel(&htim1, &sConfigOC, TIM_CHANNEL_1) != HAL_OK)
  {
    Error_Handler();
  }
  if (HAL_TIM_PWM_ConfigChannel(&htim1, &sConfigOC, TIM_CHANNEL_2) != HAL_OK)
  {
    Error_Handler();
  }
  if (HAL_TIM_PWM_ConfigChannel(&htim1, &sConfigOC, TIM_CHANNEL_3) != HAL_OK)
  {
    Error_Handler();
  }
  sBreakDeadTimeConfig.OffStateRunMode = TIM_OSSR_DISABLE;
  sBreakDeadTimeConfig.OffStateIDLEMode = TIM_OSSI_DISABLE;
  sBreakDeadTimeConfig.LockLevel = TIM_LOCKLEVEL_OFF;
  sBreakDeadTimeConfig.DeadTime = 0;
  sBreakDeadTimeConfig.BreakState = TIM_BREAK_DISABLE;
  sBreakDeadTimeConfig.BreakPolarity = TIM_BREAKPOLARITY_HIGH;
  sBreakDeadTimeConfig.BreakFilter = 0;
  sBreakDeadTimeConfig.BreakAFMode = TIM_BREAK_AFMODE_INPUT;
  sBreakDeadTimeConfig.Break2State = TIM_BREAK2_DISABLE;
  sBreakDeadTimeConfig.Break2Polarity = TIM_BREAK2POLARITY_HIGH;
  sBreakDeadTimeConfig.Break2Filter = 0;
  sBreakDeadTimeConfig.Break2AFMode = TIM_BREAK_AFMODE_INPUT;
  sBreakDeadTimeConfig.AutomaticOutput = TIM_AUTOMATICOUTPUT_DISABLE;
  if (HAL_TIMEx_ConfigBreakDeadTime(&htim1, &sBreakDeadTimeConfig) != HAL_OK)
  {
    Error_Handler();
  }
  HAL_TIM_MspPostInit(&htim1);

}

static void MX_TIM4_Init(void)
{

  TIM_ClockConfigTypeDef sClockSourceConfig = {0};
  TIM_MasterConfigTypeDef sMasterConfig = {0};

  htim4.Instance = TIM4;
  htim4.Init.Prescaler = 0;
  htim4.Init.CounterMode = TIM_COUNTERMODE_UP;
  htim4.Init.Period = 65535;
  htim4.Init.ClockDivision = TIM_CLOCKDIVISION_DIV1;
  htim4.Init.AutoReloadPreload = TIM_AUTORELOAD_PRELOAD_DISABLE;
  if (HAL_TIM_Base_Init(&htim4) != HAL_OK)
  {
    Error_Handler();
  }
  sClockSourceConfig.ClockSource = TIM_CLOCKSOURCE_INTERNAL;
  if (HAL_TIM_ConfigClockSource(&htim4, &sClockSourceConfig) != HAL_OK)
  {
    Error_Handler();
  }
  sMasterConfig.MasterOutputTrigger = TIM_TRGO_RESET;
  sMasterConfig.MasterSlaveMode = TIM_MASTERSLAVEMODE_DISABLE;
  if (HAL_TIMEx_MasterConfigSynchronization(&htim4, &sMasterConfig) != HAL_OK)
  {
    Error_Handler();
  }

}

static void MX_USART1_UART_Init(void)
{

  huart1.Instance = USART1;
  huart1.Init.BaudRate = 115200;
  huart1.Init.WordLength = UART_WORDLENGTH_8B;
  huart1.Init.StopBits = UART_STOPBITS_1;
  huart1.Init.Parity = UART_PARITY_NONE;
  huart1.Init.Mode = UART_MODE_TX_RX;
  huart1.Init.HwFlowCtl = UART_HWCONTROL_NONE;
  huart1.Init.OverSampling = UART_OVERSAMPLING_16;
  huart1.Init.OneBitSampling = UART_ONE_BIT_SAMPLE_DISABLE;
  huart1.Init.ClockPrescaler = UART_PRESCALER_DIV1;
  huart1.AdvancedInit.AdvFeatureInit = UART_ADVFEATURE_NO_INIT;
  if (HAL_UART_Init(&huart1) != HAL_OK)
  {
    Error_Handler();
  }
  if (HAL_UARTEx_SetTxFifoThreshold(&huart1, UART_TXFIFO_THRESHOLD_1_8) != HAL_OK)
  {
    Error_Handler();
  }
  if (HAL_UARTEx_SetRxFifoThreshold(&huart1, UART_RXFIFO_THRESHOLD_1_8) != HAL_OK)
  {
    Error_Handler();
  }
  if (HAL_UARTEx_DisableFifoMode(&huart1) != HAL_OK)
  {
    Error_Handler();
  }

}

static void MX_DMA_Init(void)
{

  /* DMA controller clock enable */
  __HAL_RCC_DMAMUX1_CLK_ENABLE();
  __HAL_RCC_DMA1_CLK_ENABLE();
  __HAL_RCC_DMA2_CLK_ENABLE();

  /* Configure DMA request hdma_memtomem_dma1_channel4 on DMA1_Channel4 */
  hdma_memtomem_dma1_channel4.Instance = DMA1_Channel4;
  hdma_memtomem_dma1_channel4.Init.Request = DMA_REQUEST_MEM2MEM;
  hdma_memtomem_dma1_channel4.Init.Direction = DMA_MEMORY_TO_MEMORY;
  hdma_memtomem_dma1_channel4.Init.PeriphInc = DMA_PINC_ENABLE;
  hdma_memtomem_dma1_channel4.Init.MemInc = DMA_MINC_ENABLE;
  hdma_memtomem_dma1_channel4.Init.PeriphDataAlignment = DMA_PDATAALIGN_HALFWORD;
  hdma_memtomem_dma1_channel4.Init.MemDataAlignment = DMA_MDATAALIGN_HALFWORD;
  hdma_memtomem_dma1_channel4.Init.Mode = DMA_NORMAL;
  hdma_memtomem_dma1_channel4.Init.Priority = DMA_PRIORITY_LOW;
  if (HAL_DMA_Init(&hdma_memtomem_dma1_channel4) != HAL_OK)
  {
    Error_Handler( );
  }

  /* Configure DMA request hdma_memtomem_dma1_channel5 on DMA1_Channel5 */
  hdma_memtomem_dma1_channel5.Instance = DMA1_Channel5;
  hdma_memtomem_dma1_channel5.Init.Request = DMA_REQUEST_MEM2MEM;
  hdma_memtomem_dma1_channel5.Init.Direction = DMA_MEMORY_TO_MEMORY;
  hdma_memtomem_dma1_channel5.Init.PeriphInc = DMA_PINC_ENABLE;
  hdma_memtomem_dma1_channel5.Init.MemInc = DMA_MINC_ENABLE;
  hdma_memtomem_dma1_channel5.Init.PeriphDataAlignment = DMA_PDATAALIGN_HALFWORD;
  hdma_memtomem_dma1_channel5.Init.MemDataAlignment = DMA_MDATAALIGN_HALFWORD;
  hdma_memtomem_dma1_channel5.Init.Mode = DMA_NORMAL;
  hdma_memtomem_dma1_channel5.Init.Priority = DMA_PRIORITY_LOW;
  if (HAL_DMA_Init(&hdma_memtomem_dma1_channel5) != HAL_OK)
  {
    Error_Handler( );
  }

  /* DMA interrupt init */
  /* DMA1_Channel1_IRQn interrupt configuration */
  HAL_NVIC_SetPriority(DMA1_Channel1_IRQn, 1, 0);
  HAL_NVIC_EnableIRQ(DMA1_Channel1_IRQn);
  /* DMA1_Channel2_IRQn interrupt configuration */
  HAL_NVIC_SetPriority(DMA1_Channel2_IRQn, 1, 0);
  HAL_NVIC_EnableIRQ(DMA1_Channel2_IRQn);
  /* DMA1_Channel3_IRQn interrupt configuration */
  HAL_NVIC_SetPriority(DMA1_Channel3_IRQn, 1, 0);
  HAL_NVIC_EnableIRQ(DMA1_Channel3_IRQn);
  /* DMA2_Channel1_IRQn interrupt configuration */
  HAL_NVIC_SetPriority(DMA2_Channel1_IRQn, 0, 0);
  HAL_NVIC_EnableIRQ(DMA2_Channel1_IRQn);
  /* DMA2_Channel2_IRQn interrupt configuration */
  HAL_NVIC_SetPriority(DMA2_Channel2_IRQn, 0, 0);
  HAL_NVIC_EnableIRQ(DMA2_Channel2_IRQn);

}

static void MX_GPIO_Init(void)
{
  GPIO_InitTypeDef GPIO_InitStruct = {0};

  /* GPIO Ports Clock Enable */
  __HAL_RCC_GPIOE_CLK_ENABLE();
  __HAL_RCC_GPIOF_CLK_ENABLE();
  __HAL_RCC_GPIOG_CLK_ENABLE();
  __HAL_RCC_GPIOC_CLK_ENABLE();
  __HAL_RCC_GPIOA_CLK_ENABLE();
  __HAL_RCC_GPIOB_CLK_ENABLE();
  __HAL_RCC_GPIOD_CLK_ENABLE();

  /*Configure GPIO pin Output Level */
  HAL_GPIO_WritePin(WAKE_GPIO_Port, WAKE_Pin, GPIO_PIN_RESET);

  /*Configure GPIO pin Output Level */
  HAL_GPIO_WritePin(NCD15_GPIO_Port, NCD15_Pin, GPIO_PIN_RESET);

  /*Configure GPIO pin Output Level */
  HAL_GPIO_WritePin(NSS_GPIO_Port, NSS_Pin, GPIO_PIN_RESET);

  /*Configure GPIO pin Output Level */
  HAL_GPIO_WritePin(LED_GPIO_Port, LED_Pin, GPIO_PIN_RESET);

  /*Configure GPIO pins : NC_Pin NCE3_Pin NCE4_Pin NCE5_Pin
                           NCE6_Pin NCE0_Pin NCE1_Pin */
  GPIO_InitStruct.Pin = NC_Pin|NCE3_Pin|NCE4_Pin|NCE5_Pin
                          |NCE6_Pin|NCE0_Pin|NCE1_Pin;
  GPIO_InitStruct.Mode = GPIO_MODE_ANALOG;
  GPIO_InitStruct.Pull = GPIO_NOPULL;
  HAL_GPIO_Init(GPIOE, &GPIO_InitStruct);

  /*Configure GPIO pins : NCF9_Pin NCF10_Pin NCF2_Pin */
  GPIO_InitStruct.Pin = NCF9_Pin|NCF10_Pin|NCF2_Pin;
  GPIO_InitStruct.Mode = GPIO_MODE_ANALOG;
  GPIO_InitStruct.Pull = GPIO_NOPULL;
  HAL_GPIO_Init(GPIOF, &GPIO_InitStruct);

  /*Configure GPIO pin : NRST_Pin */
  GPIO_InitStruct.Pin = NRST_Pin;
  GPIO_InitStruct.Mode = GPIO_MODE_INPUT;
  GPIO_InitStruct.Pull = GPIO_NOPULL;
  HAL_GPIO_Init(NRST_GPIO_Port, &GPIO_InitStruct);

  /*Configure GPIO pin : WAKE_Pin */
  GPIO_InitStruct.Pin = WAKE_Pin;
  GPIO_InitStruct.Mode = GPIO_MODE_OUTPUT_PP;
  GPIO_InitStruct.Pull = GPIO_NOPULL;
  GPIO_InitStruct.Speed = GPIO_SPEED_FREQ_LOW;
  HAL_GPIO_Init(WAKE_GPIO_Port, &GPIO_InitStruct);

  /*Configure GPIO pins : READY_Pin NFAULT_Pin */
  GPIO_InitStruct.Pin = READY_Pin|NFAULT_Pin;
  GPIO_InitStruct.Mode = GPIO_MODE_INPUT;
  GPIO_InitStruct.Pull = GPIO_NOPULL;
  HAL_GPIO_Init(GPIOE, &GPIO_InitStruct);

  /*Configure GPIO pins : NCB11_Pin NCB12_Pin NCB13_Pin NCB14_Pin
                           NCB15_Pin */
  GPIO_InitStruct.Pin = NCB11_Pin|NCB12_Pin|NCB13_Pin|NCB14_Pin
                          |NCB15_Pin;
  GPIO_InitStruct.Mode = GPIO_MODE_ANALOG;
  GPIO_InitStruct.Pull = GPIO_NOPULL;
  HAL_GPIO_Init(GPIOB, &GPIO_InitStruct);

  /*Configure GPIO pins : NCD8_Pin NCD9_Pin NCD10_Pin NCD11_Pin
                           NCD12_Pin NCD13_Pin NCD14_Pin NCD0_Pin
                           NCD1_Pin NCD3_Pin NCD4_Pin NCD5_Pin
                           NCD6_Pin NCD7_Pin */
  GPIO_InitStruct.Pin = NCD8_Pin|NCD9_Pin|NCD10_Pin|NCD11_Pin
                          |NCD12_Pin|NCD13_Pin|NCD14_Pin|NCD0_Pin
                          |NCD1_Pin|NCD3_Pin|NCD4_Pin|NCD5_Pin
                          |NCD6_Pin|NCD7_Pin;
  GPIO_InitStruct.Mode = GPIO_MODE_ANALOG;
  GPIO_InitStruct.Pull = GPIO_NOPULL;
  HAL_GPIO_Init(GPIOD, &GPIO_InitStruct);

  /*Configure GPIO pin : NCD15_Pin */
  GPIO_InitStruct.Pin = NCD15_Pin;
  GPIO_InitStruct.Mode = GPIO_MODE_OUTPUT_PP;
  GPIO_InitStruct.Pull = GPIO_NOPULL;
  GPIO_InitStruct.Speed = GPIO_SPEED_FREQ_LOW;
  HAL_GPIO_Init(NCD15_GPIO_Port, &GPIO_InitStruct);

  /*Configure GPIO pins : NCC6_Pin NCC7_Pin NCC10_Pin NCC11_Pin
                           NCC12_Pin */
  GPIO_InitStruct.Pin = NCC6_Pin|NCC7_Pin|NCC10_Pin|NCC11_Pin
                          |NCC12_Pin;
  GPIO_InitStruct.Mode = GPIO_MODE_ANALOG;
  GPIO_InitStruct.Pull = GPIO_NOPULL;
  HAL_GPIO_Init(GPIOC, &GPIO_InitStruct);

  /*Configure GPIO pin : NSS_Pin */
  GPIO_InitStruct.Pin = NSS_Pin;
  GPIO_InitStruct.Mode = GPIO_MODE_OUTPUT_PP;
  GPIO_InitStruct.Pull = GPIO_NOPULL;
  GPIO_InitStruct.Speed = GPIO_SPEED_FREQ_LOW;
  HAL_GPIO_Init(NSS_GPIO_Port, &GPIO_InitStruct);

  /*Configure GPIO pin : LED_Pin */
  GPIO_InitStruct.Pin = LED_Pin;
  GPIO_InitStruct.Mode = GPIO_MODE_OUTPUT_PP;
  GPIO_InitStruct.Pull = GPIO_NOPULL;
  GPIO_InitStruct.Speed = GPIO_SPEED_FREQ_LOW;
  HAL_GPIO_Init(LED_GPIO_Port, &GPIO_InitStruct);

}

void Error_Handler(void)
{
  __disable_irq();
  while (1)
  {
  }
}
